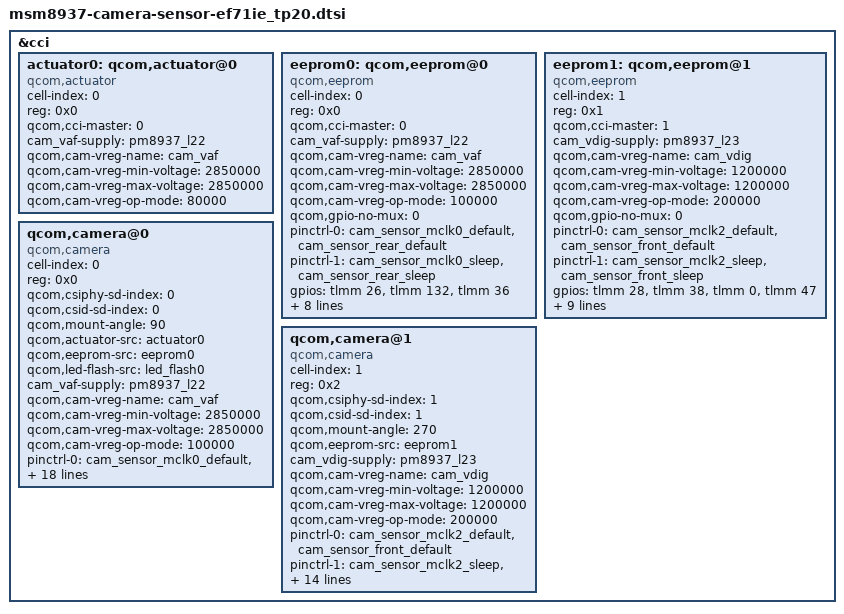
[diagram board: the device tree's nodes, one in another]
/*
 * Copyright (c) 2015, The Linux Foundation. All rights reserved.
 *
 * This program is free software; you can redistribute it and/or modify
 * it under the terms of the GNU General Public License version 2 and
 * only version 2 as published by the Free Software Foundation.
 *
 * This program is distributed in the hope that it will be useful,
 * but WITHOUT ANY WARRANTY; without even the implied warranty of
 * MERCHANTABILITY or FITNESS FOR A PARTICULAR PURPOSE.  See the
 * GNU General Public License for more details.
 */

&cci {
	actuator0: qcom,actuator@0 {
		cell-index = <0>;
		reg = <0x0>;
		compatible = "qcom,actuator";
		qcom,cci-master = <0>;
		cam_vaf-supply = <&pm8937_l22>;
		qcom,cam-vreg-name = "cam_vaf";
		qcom,cam-vreg-min-voltage = <2850000>;
		qcom,cam-vreg-max-voltage = <2850000>;
		qcom,cam-vreg-op-mode = <80000>;
	};
/*	
	led_flash1: qcom,camera-flash@a6 {
		cell-index = <1>;
		reg = <0xa6>;
		qcom,slave-id = <0xa6 0x00 0x00>;
		compatible = "qcom,camera-flash";	
		//label = "lm3559";
		qcom,flash-type = <1>;
		qcom,gpio-no-mux = <0>;
		qcom,enable_pinctrl;
		pinctrl-names = "cam_default", "cam_suspend";
		pinctrl-0 = <&flash_led_enable>;
		pinctrl-1 = <&flash_led_disable>;
		gpios = <&tlmm 33 0>,
			<&tlmm 34 0>,
			<&tlmm 132 0>; //for FlashLight
		qcom,gpio-flash-en = <0>;
		qcom,gpio-flash-now = <1>;
		qcom,gpio-iovdd-en = <2>;
		qcom,gpio-req-tbl-num = <0 1 2>;
		qcom,gpio-req-tbl-flags = <0 0 0>;
		qcom,gpio-req-tbl-label = "FLASH_EN",
			"FLASH_NOW",
			"CAM_IOVDD0";
		qcom,cci-master = <0>;
	};
*/
	eeprom0: qcom,eeprom@0 {
		cell-index = <0>;
		reg = <0x0>;
		compatible = "qcom,eeprom";
		qcom,cci-master = <0>;
/*
		qcom,eeprom-name = "dw9763";
		qcom,slave-addr = <0xb0>;
		qcom,num-blocks = <8>;

		qcom,page0 = <0 0x0 0 0x0 0 0>;
		qcom,poll0 = <0 0x0 0 0x0 0 0>;
		qcom,mem0 = <6 0x0 2 0 1 0>; //AWB

		qcom,page1 = <0 0x0 0 0x0 0 0>;
		qcom,poll1 = <0 0x0 0 0x0 0 0>;
		qcom,mem1 = <2 0x1400 2 0 1 0>; //checksum 5100K_AWB

		qcom,page2 = <0 0x0 0 0x0 0 0>;
		qcom,poll2 = <0 0x0 0 0x0 0 0>;
		qcom,mem2 = <884 0x400 2 0 1 0>; //LSC

		qcom,page3 = <0 0x0 0 0x0 0 0>;
		qcom,poll3 = <0 0x0 0 0x0 0 0>;
		qcom,mem3 = <2 0x1402 2 0 1 0>; //checksum 5100K_LSC

		qcom,page4 = <0 0x0 0 0x0 0 0>;
		qcom,poll4 = <0 0x0 0 0x0 0 0>;
		qcom,mem4 = <6 0x1000 2 0 1 0>; // AF infinity

		qcom,page5 = <0 0x0 0 0x0 0 0>;
		qcom,poll5 = <0 0x0 0 0x0 0 0>;
		qcom,mem5 =  <2 0x1408 2 0 1 0>; //checksum AF

		qcom,page6 = <0 0x0 0 0x0 0 0>;
		qcom,poll6 = <0 0x0 0 0x0 0 0>;
		qcom,mem6 = <4 0x140a 2 0 1 0>; //date, version

		qcom,page7 = <0 0x0 0 0x0 0 0>;
		qcom,poll7 = <0 0x0 0 0x0 0 0>;
		qcom,mem7 = <0 0x0 0 0 0 0>;
*/
		cam_vaf-supply = <&pm8937_l22>;
		qcom,cam-vreg-name = "cam_vaf";
		qcom,cam-vreg-min-voltage = <2850000>;
		qcom,cam-vreg-max-voltage = <2850000>;
		qcom,cam-vreg-op-mode = <100000>;
		qcom,gpio-no-mux = <0>;
		pinctrl-names = "cam_default", "cam_suspend";
		pinctrl-0 = <&cam_sensor_mclk0_default
				&cam_sensor_rear_default>;
		pinctrl-1 = <&cam_sensor_mclk0_sleep &cam_sensor_rear_sleep>;
		gpios = <&tlmm 26 0>,
			<&tlmm 132 0>,
			<&tlmm 36 0>;
		qcom,gpio-iovdd-en = <1>;
		qcom,gpio-reset = <2>;
		qcom,gpio-req-tbl-num = <0 1 2>;
		qcom,gpio-req-tbl-flags = <1 0 0>;
		qcom,gpio-req-tbl-label = "CAMIF_MCLK0",
			"CAM_RESET0",
			"CAM_IOVDD0";
/*
		qcom,cam-power-seq-type = "sensor_vreg", "sensor_gpio", "sensor_gpio", "sensor_clk";
		qcom,cam-power-seq-val = "cam_vaf", "sensor_gpio_iovdd_en", "sensor_gpio_reset", "sensor_cam_mclk";
		qcom,cam-power-seq-cfg-val = <1 1 1 24000000>;
		qcom,cam-power-seq-delay = <1 1 3 3>;
*/
		status = "ok";
		clocks = <&clock_gcc clk_mclk0_clk_src>,
				<&clock_gcc clk_gcc_camss_mclk0_clk>;
		clock-names = "cam_src_clk", "cam_clk";
	};

	eeprom1: qcom,eeprom@1 {
		cell-index = <1>;
		reg = <0x1>;
		compatible = "qcom,eeprom";
		qcom,cci-master = <1>;
/*
		qcom,eeprom-name = "s5k5e2";
		qcom,slave-addr = <0x20>;
		qcom,i2c-freq-mode = <2>;
		qcom,num-blocks = <5>;

		qcom,page0 = <1 0x0A00 2 0x04 1 0>; // make init
		qcom,pageen0 = <1 0x0A02 2 0x02 1 0>; // set page 2
		qcom,poll0 = <1 0x0A00 2 0x01 1 10>; //set read mode
		qcom,mem0 = <13 0x0A04 2 0 1 0>; //AWB(6), VER(2), CSUM(4), PAGE Flag(1)

		qcom,page1 = <1 0x0A00 2 0x04 1 0>;
		qcom,pageen1 = <1 0x0A02 2 0x03 1 0>; // set page 3
		qcom,poll1 = <1 0x0A00 2 0x01 1 10>;
		qcom,mem1 = <12 0x0A04 2 0 1 0>;

		qcom,page2 = <1 0x0A00 2 0x04 1 0>;
		qcom,pageen2 = <1 0x0A02 2 0x04 1 0>; // set page 4
		qcom,poll2 = <1 0x0A00 2 0x01 1 10>;
		qcom,mem2 = <12 0x0A04 2 0 1 0>;

		qcom,page3 = <1 0x0A00 2 0x04 1 0>;
		qcom,pageen3 = <1 0x0A02 2 0x05 1 0>; // set page 5
		qcom,poll3 = <1 0x0A00 2 0x01 1 10>;
		qcom,mem3 = <12 0x0A04 2 0 1 0>;

		qcom,page4 = <1 0x0A00 2 0x04 1 0>; //make init
		qcom,pageen4 = <1 0x0A00 2 0x00 1 0>; //disable NVM
		qcom,poll4 = <0 0x0 0 0x0 0 0>;
		qcom,mem4 = <0 0x0 0 0x0 0 0>;
*/
		cam_vdig-supply = <&pm8937_l23>;
		qcom,cam-vreg-name = "cam_vdig";
		qcom,cam-vreg-min-voltage = <1200000>;
		qcom,cam-vreg-max-voltage = <1200000>;
		qcom,cam-vreg-op-mode = <200000>;
		qcom,gpio-no-mux = <0>;
		pinctrl-names = "cam_default", "cam_suspend";
		pinctrl-0 = <&cam_sensor_mclk2_default
				&cam_sensor_front_default>;
		pinctrl-1 = <&cam_sensor_mclk2_sleep &cam_sensor_front_sleep>;
		gpios = <&tlmm 28 0>,
			<&tlmm 38 0>, /* CAM1_RST_N */
			<&tlmm 0 0>, /* 5M_AVDD_EN */
			<&tlmm 47 0>; /* 5M_VDDIO_EN */
		qcom,gpio-reset = <1>;
		qcom,gpio-avdd-en = <2>;
		qcom,gpio-vddio-en = <3>;
		qcom,gpio-req-tbl-num = <0 1 2 3>;
		qcom,gpio-req-tbl-flags = <1 0 0 0>;
		qcom,gpio-req-tbl-label = "CAMIF_MCLK2",
			"CAM_RESET1",
			"CAM_AVDD1",
			"CAM_VDDIO1";
/*
		qcom,cam-power-seq-type = "sensor_vreg", "sensor_gpio", "sensor_gpio", "sensor_gpio", "sensor_clk";
		qcom,cam-power-seq-val = "cam_vdig", "sensor_gpio_avdd_en", "sensor_gpio_vddio_en", "sensor_gpio_reset", "sensor_cam_mclk";
		qcom,cam-power-seq-cfg-val = <1 1 1 1 24000000>;
		qcom,cam-power-seq-delay = <10 10 10 30 30>;
*/
		status = "ok";
		clocks = <&clock_gcc clk_mclk2_clk_src>,
				<&clock_gcc clk_gcc_camss_mclk2_clk>;
		clock-names = "cam_src_clk", "cam_clk";
	};

	qcom,camera@0 {
		cell-index = <0>;
		compatible = "qcom,camera";
		reg = <0x0>;
		qcom,csiphy-sd-index = <0>;
		qcom,csid-sd-index = <0>;
		qcom,mount-angle = <90>;
		qcom,actuator-src = <&actuator0>;
		qcom,eeprom-src = <&eeprom0>;
		qcom,led-flash-src = <&led_flash0>;
		cam_vaf-supply = <&pm8937_l22>;	/* VREG_L22_2P85_CAM_AVDD , VREG_L17_2P85_CAMAF */
		qcom,cam-vreg-name = "cam_vaf";
		qcom,cam-vreg-min-voltage = <2850000>;
		qcom,cam-vreg-max-voltage = <2850000>;
		qcom,cam-vreg-op-mode = <100000>;
		pinctrl-names = "cam_default", "cam_suspend";
		pinctrl-0 = <&cam_sensor_mclk0_default
				&cam_sensor_rear_default>;
		pinctrl-1 = <&cam_sensor_mclk0_sleep &cam_sensor_rear_sleep>;
		gpios = <&tlmm 26 0>,
			<&tlmm 36 0>,	/* CAM0_RST_N */
			<&tlmm 92 0>,	/* 13M_DVDD_EN */
			<&tlmm 132 0>,	/* 13M_IOVDD_EN */
			<&tlmm 133 0>;	/* 13M_AVDD_EN */
		qcom,gpio-reset = <1>;
		qcom,gpio-dvdd-en = <2>;
		qcom,gpio-iovdd-en = <3>;
		qcom,gpio-avdd-en = <4>;
		qcom,gpio-req-tbl-num = <0 1 2 3 4>;
		qcom,gpio-req-tbl-flags = <1 0 0 0 0>;
		qcom,gpio-req-tbl-label = "CAMIF_MCLK0",
			"CAM_RESET0",
			"CAM_DVDD0",
			"CAM_IOVDD0",
			"CAM_AVDD0";
		qcom,sensor-position = <0>;
		qcom,sensor-mode = <0>;
		qcom,cci-master = <0>;
		status = "ok";
		clocks = <&clock_gcc clk_mclk0_clk_src>,
				<&clock_gcc clk_gcc_camss_mclk0_clk>;
		clock-names = "cam_src_clk", "cam_clk";
	};
	
	qcom,camera@1 {
		cell-index = <1>;
		compatible = "qcom,camera";
		reg = <0x2>;
		qcom,csiphy-sd-index = <1>;
		qcom,csid-sd-index = <1>;
		qcom,mount-angle = <270>;
		qcom,eeprom-src = <&eeprom1>;
		cam_vdig-supply = <&pm8937_l23>;
		qcom,cam-vreg-name = "cam_vdig";
		qcom,cam-vreg-min-voltage = <1200000>;
		qcom,cam-vreg-max-voltage = <1200000>;
		qcom,cam-vreg-op-mode = <200000>;
		pinctrl-names = "cam_default", "cam_suspend";
		pinctrl-0 = <&cam_sensor_mclk2_default
				&cam_sensor_front_default>;
		pinctrl-1 = <&cam_sensor_mclk2_sleep
				&cam_sensor_front_sleep>;
		gpios = <&tlmm 28 0>,
			<&tlmm 38 0>,	/* CAM1_RST_N */
			<&tlmm 0 0>,	/* 5M_AVDD_EN */
			<&tlmm 47 0>;	/* 5M_VDDIO_EN */
		qcom,gpio-reset = <1>;
		qcom,gpio-avdd-en = <2>;
		qcom,gpio-vddio-en = <3>;
		qcom,gpio-req-tbl-num = <0 1 2 3>;
		qcom,gpio-req-tbl-flags = <1 0 0 0>;
		qcom,gpio-req-tbl-label = "CAMIF_MCLK2",
			"CAM_RESET1",
			"CAM_AVDD1",
			"CAM_VDDIO1";
		qcom,sensor-position = <1>;
		qcom,sensor-mode = <1>;
		qcom,cci-master = <1>;
		status = "ok";
		clocks = <&clock_gcc clk_mclk2_clk_src>,
				<&clock_gcc clk_gcc_camss_mclk2_clk>;
		clock-names = "cam_src_clk", "cam_clk";
	};
};
